# netx90_app register map
File version: 1.0
CPU: CM4 r0p1, little endian, MPU, FPU, 4 interrupt priority bits, 78 interrupts
Registers are 32-bit, read-write, reset 0x0 unless marked. A register's access mark holds for its fields unless they carry their own. Offsets are from the block's base; [hi:lo] are bit positions; 'fields as' and 'values as' point back to an identical list.

## wdg_xpic_app
Base 0xFF900180
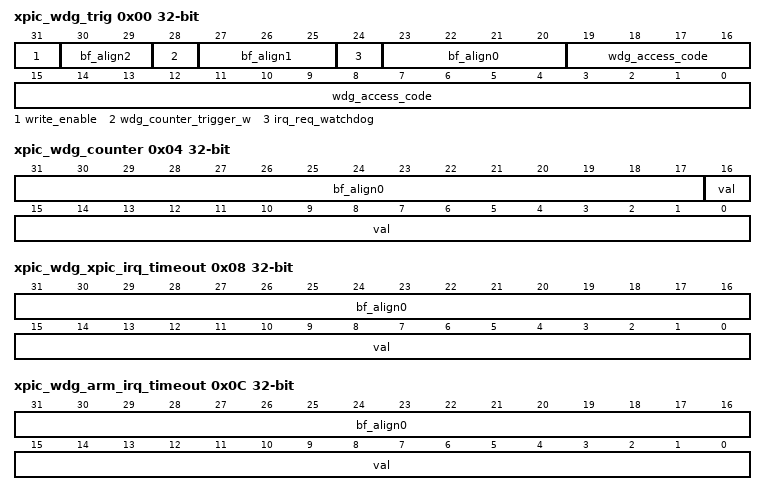
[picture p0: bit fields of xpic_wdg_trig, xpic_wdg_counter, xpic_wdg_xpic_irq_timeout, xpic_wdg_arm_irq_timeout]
0x00 xpic_wdg_trig (reset mask 0x910FFFFF) — netX xPIC Watchdog Trigger Register. The watchdog access code is generated by a pseudo random generator.
  [31] write_enable — Write enable bit for timeout register: As long as this bit is not set all write accesses to the timeout register are ignored.
  [30:29] bf_align2 — bitField alignment value for aeabi compatibility
  [28] wdg_counter_trigger_w — Watchdog trigger bit: Bit must be set to trigger the watchdog counter. When read, this bit is always '0'
  [27:25] bf_align1 — bitField alignment value for aeabi compatibility
  [24] irq_req_watchdog — xPIC IRQ request of watchdog, writing 1 deletes IRQ to xPIC
  [23:20] bf_align0 — bitField alignment value for aeabi compatibility
  [19:0] wdg_access_code — Watchdog access code for triggering. A read access gives the next 16 bit code for trigger. A write access with correct access code will trigger the watchdog counter.
0x04 xpic_wdg_counter ro (reset mask 0x1FFFF) — netX xPIC Watchdog Counter Register The counter value is decremented each 10000 system clock cycles.
  [31:17] bf_align0 — bitField alignment value for aeabi compatibility
  [16:0] val — Actual watchdog counter value: Bit 16 shows: 1: Watchdog is counting down from xpic_irq_timeout to 0 for xPIC-IRQ 0: Watchdog is counting down from arm_irq_timeout to 0 for ARM-IRQ
0x08 xpic_wdg_xpic_irq_timeout (reset mask 0xFFFF) — netX xPIC Watchdog xPIC interrupt timout register: xpic_irq_timeout or arm_irq_timeout must be nonzero to enable watchdog
  [31:16] bf_align0 — bitField alignment value for aeabi compatibility
  [15:0] val — Watchdog interrupt timeout The total xpic_irq timeout for a netX clock of 100MHz is: xpic_wdg_xpic_irq_timeout * 100us
0x0C xpic_wdg_arm_irq_timeout (reset mask 0xFFFF) — netX xPIC Watchdog ARM interrupt timout register: xpic_irq_timeout or arm_irq_timeout must be nonzero to enable watchdog
  [31:16] bf_align0 — bitField alignment value for aeabi compatibility
  [15:0] val — Watchdog ARM interrupt timeout The total arm_irq timeout for a netX clock of 100MHz is: (xpic_wdg_xpic_irq_timeout + xpic_wdg_arm_irq_timeout) * 100us
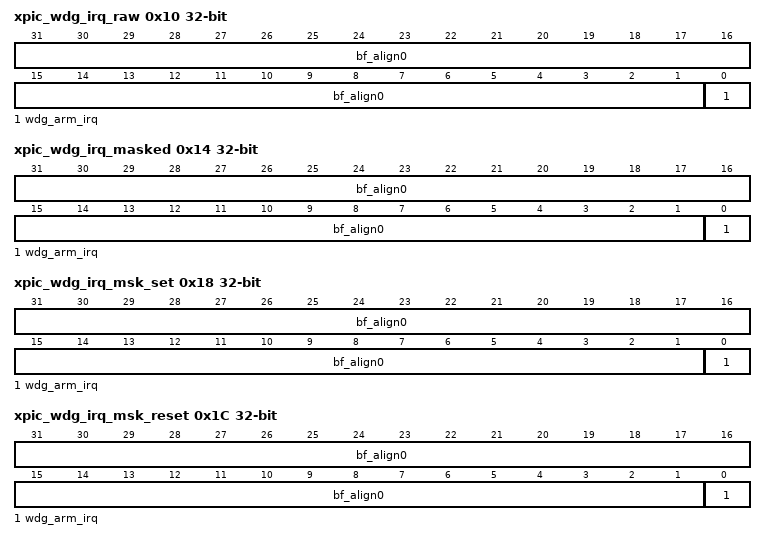
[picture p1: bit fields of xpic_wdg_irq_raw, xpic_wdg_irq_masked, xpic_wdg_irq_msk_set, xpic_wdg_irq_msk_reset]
0x10 xpic_wdg_irq_raw (reset mask 0x1) — Read access shows status of unmasked IRQs. IRQs are set automatically and reset by writing to this register: Write access with '1' resets the appropriate IRQ. Write access with '0' does not influence this bit.
  [31:1] bf_align0 — bitField alignment value for aeabi compatibility
  [0] wdg_arm_irq — Interrupt from xPIC Watchdog to ARM
0x14 xpic_wdg_irq_masked ro (reset mask 0x1) — xpic_wdg Masked IRQ register: Shows status of masked IRQs (as connected to xPIC).
  fields as xpic_wdg_irq_raw
0x18 xpic_wdg_irq_msk_set (reset mask 0x1) — xpic_wdg interrupt mask enable: The IRQ mask enables interrupt requests for corresponding interrupt sources. As its bits might be changed by different software tasks, the IRQ mask register is not writable directly, but by set and reset masks: Write access with '1' sets interrupt mask bit (enables interrupt request for corresponding interrupt source). Write access with '0' does not influence this bit. Read access shows actual interrupt mask. Attention: Before activating interrupt mask, delete old pending interrupts by writing the same value to wdg_irq_raw.
  fields as xpic_wdg_irq_raw
0x1C xpic_wdg_irq_msk_reset (reset mask 0x1) — xpic_wdg interrupt mask disable: This is the corresponding reset mask to disable interrupt requests for corresponding interrupt sources: Write access with '1' resets interrupt mask bit (disables interrupt request for corresponding interrupt source). Write access with '0' does not influence this bit. Read access shows actual interrupt mask.
  fields as xpic_wdg_irq_raw
